VERSION ""

NS_ :

BS_:

BU_: radar Camera ADAS
VAL_TABLE_ vtSig_MCPB_ID 0 "No MCPB" ;
VAL_TABLE_ VtPHASE_VIE 7 "Not used 0x7" 6 "Not used 0x6" 5 "Not used 0x5" 4 "COM_OFF" 3 "Wake / Reveil" 2 "SwitchToStandby / Mise en Veille" 1 "Normal" 0 "Standby / Veille" ;
VAL_TABLE_ LaneCrossing_valueTable 1 "crossing" 0 "not crossing" ;
VAL_TABLE_ LaneModuleValid_vlaueTable 1 "valid" 0 "not valid" ;
VAL_TABLE_ CloseRangeCutIn_ValueTable 1 "Cut in" 0 "No cut in" ;
VAL_TABLE_ LaneMoveType_valueTable 3 "Right movement" 2 "Left movement" 1 "Stable" 0 "Undefined" ;
VAL_TABLE_ MotionStatus_valueTable 8 "Moving (oncoming)" 7 "Unknown (oncoming)" 6 "Stopped (oncoming)" 5 "Moving (movable)" 4 "Unknown (movable)" 3 "Stopped (movable)" 2 "Parked (never moved lights off)" 1 "Standing (never moved lights on)" 0 "Not defined" ;
VAL_TABLE_ PedInDangerZone_valueTable 3 "Invalid" 1 "Pedestrian in danger zone" 0 "No pedestrian in danger zone" ;
VAL_TABLE_ Ped_FCW_on_valueTable 3 "Invalid" 1 "Warning active" 0 "No warning" ;
VAL_TABLE_ FCW_on_valueTable 1 "Warning active" 0 "No warning" ;
VAL_TABLE_ VLviewRangeAvail_valueTable 1 "available" 0 "not available" ;
VAL_TABLE_ VLlaneType_valueTable 6 "road edge" 5 "bott's dotts" 4 "double lane mark" 3 "solid" 2 "dashed" 1 "undecided" 0 "invalid" ;
VAL_TABLE_ VLquality_valueTable 1 "high" 0 "low" ;
VAL_TABLE_ Failsafe_valueTable 16 "partial transparent" 8 "partial blockage" 4 "low sun" 2 "saturated image" 1 "blurred image" ;
VAL_TABLE_ DayTimeIndicator_valueTable 2 "night" 1 "dusk" 0 "day" ;
VAL_TABLE_ VOreplacedObject_valueTable 1 "replaced" 0 "not replaced" ;
VAL_TABLE_ VOcutInAndOut_valueTable 4 "cut out" 3 "cut in" 2 "out host lane" 1 "in host lane" 0 "undefined" ;
VAL_TABLE_ VOvalid_valueTable 1 "new valid" 0 "older valid" ;
VAL_TABLE_ VOmotionStatus_valueTable 5 "parked" 4 "oncoming" 3 "moving" 2 "stopped" 1 "standing" 0 "not defined" ;
VAL_TABLE_ VObrakeLight_valueTable 2 "on" 1 "off" 0 "not available" ;
VAL_TABLE_ VOindicator_valueTable 4 "both" 3 "right" 2 "left" 1 "off" 0 "not available" ;
VAL_TABLE_ VOlane_valueTable 3 "invalid" 2 "next lane" 1 "ego" 0 "not assigned" ;
VAL_TABLE_ VOisValid_valueTable 1 "object" 0 "no object" ;
VAL_TABLE_ VOclass_valueTable 5 "pedestrian" 4 "bicycle" 3 "motorbike" 2 "car" 1 "truck" 0 "undecided" ;
VAL_TABLE_ RoadType_valueTable 2 "inner city" 1 "highway" 0 "unknown" ;
VAL_TABLE_ ConstructionArea_valueTable 1 "construction area" 0 "not construction area" ;
VAL_TABLE_ Maintenance_valueTable 1 "permanent failure" 0 "ok" ;

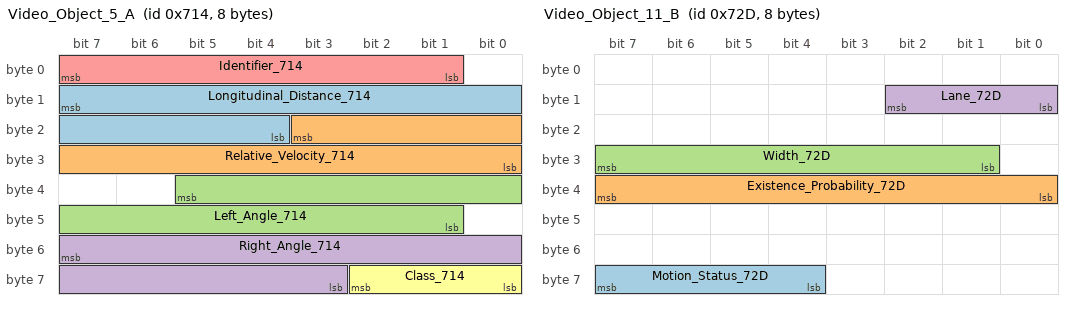
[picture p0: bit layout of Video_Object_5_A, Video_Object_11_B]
BO_ 1812 Video_Object_5_A: 8 Camera
 SG_ Longitudinal_Distance_714 : 15|12@0+ (0.05,0) [0|204.75] "m"  ADAS,radar
 SG_ Relative_Velocity_714 : 19|12@0- (0.05,0) [-102.4|102.35] "m/s"  ADAS,radar
 SG_ Left_Angle_714 : 37|13@0- (0.0002,0) [-0.8192|0.819] "rad"  ADAS,radar
 SG_ Right_Angle_714 : 55|13@0- (0.0002,0) [-0.8192|0.819] "rad"  ADAS,radar
 SG_ Identifier_714 : 7|7@0+ (1,0) [0|127] ""  ADAS,radar
 SG_ Class_714 : 58|3@0+ (1,0) [0|7] ""  ADAS,radar

BO_ 1078 Video_Object_Header: 6 Camera
 SG_ Number_Of_Objects : 7|5@0+ (1,0) [0|31] ""  radar

BO_ 1837 Video_Object_11_B: 8 Camera
 SG_ Motion_Status_72D : 63|4@0+ (1,0) [0|15] "0"  radar,ADAS
 SG_ Existence_Probability_72D : 39|8@0+ (0.0039215686,0) [0|0.999999] ""  radar,ADAS
 SG_ Width_72D : 31|7@0+ (0.05,0) [0|6.35] ""  radar,ADAS
 SG_ Lane_72D : 10|3@0+ (1,0) [0|7] ""  radar,ADAS

BO_ 1977 DL_Status: 8 radar
 SG_ Stat_StatusType : 7|1@0+ (1,0) [0|1] ""  ADAS

BO_ 1978 DL_Targets: 8 radar
 SG_ ta8_relative_velocity m68 : 21|14@0- (0.01,0) [-81.91|81.91] "m/s"  ADAS
 SG_ ta7_angle_LSB m60 : 63|3@0+ (0.05,0) [0|0.35] ""  ADAS
 SG_ ta18_angle_LSB m148 : 63|3@0+ (0.05,0) [0|0.35] ""  ADAS
 SG_ ta14_relative_velocity m116 : 21|14@0- (0.01,0) [-81.91|81.91] "m/s"  ADAS
 SG_ ta10_relative_velocity m84 : 21|14@0- (0.01,0) [-81.91|81.91] "m/s"  ADAS
 SG_ target_multiplexor M : 7|8@0+ (1,0) [0|255] ""  ADAS
 SG_ ta31_fix_relative_velocity m252 : 21|14@0- (0.01,0) [-81.91|81.91] "m/s"  ADAS
 SG_ ta31_fix_range m252 : 39|16@0+ (0.01,0) [0|655.35] "m"  ADAS
 SG_ ta31_fix_power m252 : 55|8@0+ (0.5,0) [0|127.5] "dB"  ADAS
 SG_ ta31_fix_angle_MSB m252 : 15|8@0- (0.4,0) [-51.15|51.15] ""  ADAS
 SG_ ta31_fix_angle_LSB m252 : 63|3@0+ (0.05,0) [0|0.35] ""  ADAS
 SG_ ta0_power m4 : 55|8@0+ (0.5,0) [0|127.5] "dB"  ADAS
 SG_ ta1_power m12 : 55|8@0+ (0.5,0) [0|127.5] "dB"  ADAS
 SG_ ta2_power m20 : 55|8@0+ (0.5,0) [0|127.5] "dB"  ADAS
 SG_ ta3_power m28 : 55|8@0+ (0.5,0) [0|127.5] "dB"  ADAS
 SG_ ta4_power m36 : 55|8@0+ (0.5,0) [0|127.5] "dB"  ADAS
 SG_ ta5_power m44 : 55|8@0+ (0.5,0) [0|127.5] "dB"  ADAS
 SG_ ta6_power m52 : 55|8@0+ (0.5,0) [0|127.5] "dB"  ADAS
 SG_ ta7_power m60 : 55|8@0+ (0.5,0) [0|127.5] "dB"  ADAS
 SG_ ta8_power m68 : 55|8@0+ (0.5,0) [0|127.5] "dB"  ADAS
 SG_ ta9_power m76 : 55|8@0+ (0.5,0) [0|127.5] "dB"  ADAS
 SG_ ta10_power m84 : 55|8@0+ (0.5,0) [0|127.5] "dB"  ADAS
 SG_ ta11_power m92 : 55|8@0+ (0.5,0) [0|127.5] "dB"  ADAS
 SG_ ta12_power m100 : 55|8@0+ (0.5,0) [0|127.5] "dB"  ADAS
 SG_ ta13_power m108 : 55|8@0+ (0.5,0) [0|127.5] "dB"  ADAS
 SG_ ta14_power m116 : 55|8@0+ (0.5,0) [0|127.5] "dB"  ADAS
 SG_ ta15_power m124 : 55|8@0+ (0.5,0) [0|127.5] "dB"  ADAS
 SG_ ta16_power m132 : 55|8@0+ (0.5,0) [0|127.5] "dB"  ADAS
 SG_ ta17_power m140 : 55|8@0+ (0.5,0) [0|127.5] "dB"  ADAS
 SG_ ta18_power m148 : 55|8@0+ (0.5,0) [0|127.5] "dB"  ADAS
 SG_ ta19_power m156 : 55|8@0+ (0.5,0) [0|127.5] "dB"  ADAS
 SG_ ta20_power m164 : 55|8@0+ (0.5,0) [0|127.5] "dB"  ADAS
 SG_ ta21_power m172 : 55|8@0+ (0.5,0) [0|127.5] "dB"  ADAS
 SG_ ta22_power m180 : 55|8@0+ (0.5,0) [0|127.5] "dB"  ADAS
 SG_ ta23_power m188 : 55|8@0+ (0.5,0) [0|127.5] "dB"  ADAS
 SG_ ta24_power m196 : 55|8@0+ (0.5,0) [0|127.5] "dB"  ADAS
 SG_ ta25_power m204 : 55|8@0+ (0.5,0) [0|127.5] "dB"  ADAS
 SG_ ta26_power m212 : 55|8@0+ (0.5,0) [0|127.5] "dB"  ADAS
 SG_ ta27_power m220 : 55|8@0+ (0.5,0) [0|127.5] "dB"  ADAS
 SG_ ta28_power m228 : 55|8@0+ (0.5,0) [0|127.5] "dB"  ADAS
 SG_ ta29_power m236 : 55|8@0+ (0.5,0) [0|127.5] "dB"  ADAS
 SG_ ta30_power m244 : 55|8@0+ (0.5,0) [0|127.5] "dB"  ADAS
 SG_ ta0_range m4 : 39|16@0+ (0.01,0) [0|655.35] "m"  ADAS
 SG_ ta1_range m12 : 39|16@0+ (0.01,0) [0|655.35] "m"  ADAS
 SG_ ta2_range m20 : 39|16@0+ (0.01,0) [0|655.35] "m"  ADAS
 SG_ ta3_range m28 : 39|16@0+ (0.01,0) [0|655.35] "m"  ADAS
 SG_ ta4_range m36 : 39|16@0+ (0.01,0) [0|655.35] "m"  ADAS
 SG_ ta5_range m44 : 39|16@0+ (0.01,0) [0|655.35] "m"  ADAS
 SG_ ta6_range m52 : 39|16@0+ (0.01,0) [0|655.35] "m"  ADAS
 SG_ ta7_range m60 : 39|16@0+ (0.01,0) [0|655.35] "m"  ADAS
 SG_ ta8_range m68 : 39|16@0+ (0.01,0) [0|655.35] "m"  ADAS
 SG_ ta9_range m76 : 39|16@0+ (0.01,0) [0|655.35] "m"  ADAS
 SG_ ta10_range m84 : 39|16@0+ (0.01,0) [0|655.35] "m"  ADAS
 SG_ ta11_range m92 : 39|16@0+ (0.01,0) [0|655.35] "m"  ADAS
 SG_ ta12_range m100 : 39|16@0+ (0.01,0) [0|655.35] "m"  ADAS
 SG_ ta13_range m108 : 39|16@0+ (0.01,0) [0|655.35] "m"  ADAS
 SG_ ta14_range m116 : 39|16@0+ (0.01,0) [0|655.35] "m"  ADAS
 SG_ ta15_range m124 : 39|16@0+ (0.01,0) [0|655.35] "m"  ADAS
 SG_ ta16_range m132 : 39|16@0+ (0.01,0) [0|655.35] "m"  ADAS
 SG_ ta17_range m140 : 39|16@0+ (0.01,0) [0|655.35] "m"  ADAS
 SG_ ta18_range m148 : 39|16@0+ (0.01,0) [0|655.35] "m"  ADAS
 SG_ ta19_range m156 : 39|16@0+ (0.01,0) [0|655.35] "m"  ADAS
 SG_ ta20_range m164 : 39|16@0+ (0.01,0) [0|655.35] "m"  ADAS
 SG_ ta21_range m172 : 39|16@0+ (0.01,0) [0|655.35] "m"  ADAS
 SG_ ta22_range m180 : 39|16@0+ (0.01,0) [0|655.35] "m"  ADAS
 SG_ ta23_range m188 : 39|16@0+ (0.01,0) [0|655.35] "m"  ADAS
 SG_ ta24_range m196 : 39|16@0+ (0.01,0) [0|655.35] "m"  ADAS
 SG_ ta25_range m204 : 39|16@0+ (0.01,0) [0|655.35] "m"  ADAS
 SG_ ta26_range m212 : 39|16@0+ (0.01,0) [0|655.35] "m"  ADAS
 SG_ ta27_range m220 : 39|16@0+ (0.01,0) [0|655.35] "m"  ADAS
 SG_ ta28_range m228 : 39|16@0+ (0.01,0) [0|655.35] "m"  ADAS
 SG_ ta29_range m236 : 39|16@0+ (0.01,0) [0|655.35] "m"  ADAS
 SG_ ta30_range m244 : 39|16@0+ (0.01,0) [0|655.35] "m"  ADAS
 SG_ ta0_relative_velocity m4 : 21|14@0- (0.01,0) [-81.91|81.91] "m/s"  ADAS
 SG_ ta1_relative_velocity m12 : 21|14@0- (0.01,0) [-81.91|81.91] "m/s"  ADAS
 SG_ ta2_relative_velocity m20 : 21|14@0- (0.01,0) [-81.91|81.91] "m/s"  ADAS
 SG_ ta3_relative_velocity m28 : 21|14@0- (0.01,0) [-81.91|81.91] "m/s"  ADAS
 SG_ ta4_relative_velocity m36 : 21|14@0- (0.01,0) [-81.91|81.91] "m/s"  ADAS
 SG_ ta5_relative_velocity m44 : 21|14@0- (0.01,0) [-81.91|81.91] "m/s"  ADAS
 SG_ ta6_relative_velocity m52 : 21|14@0- (0.01,0) [-81.91|81.91] "m/s"  ADAS
 SG_ ta7_relative_velocity m60 : 21|14@0- (0.01,0) [-81.91|81.91] "m/s"  ADAS
 SG_ ta9_relative_velocity m76 : 21|14@0- (0.01,0) [-81.91|81.91] "m/s"  ADAS
 SG_ ta11_relative_velocity m92 : 21|14@0- (0.01,0) [-81.91|81.91] "m/s"  ADAS
 SG_ ta12_relative_velocity m100 : 21|14@0- (0.01,0) [-81.91|81.91] "m/s"  ADAS
 SG_ ta13_relative_velocity m108 : 21|14@0- (0.01,0) [-81.91|81.91] "m/s"  ADAS
 SG_ ta15_relative_velocity m124 : 21|14@0- (0.01,0) [-81.91|81.91] "m/s"  ADAS
 SG_ ta16_relative_velocity m132 : 21|14@0- (0.01,0) [-81.91|81.91] "m/s"  ADAS
 SG_ ta17_relative_velocity m140 : 21|14@0- (0.01,0) [-81.91|81.91] "m/s"  ADAS
 SG_ ta18_relative_velocity m148 : 21|14@0- (0.01,0) [-81.91|81.91] "m/s"  ADAS
 SG_ ta19_relative_velocity m156 : 21|14@0- (0.01,0) [-81.91|81.91] "m/s"  ADAS
 SG_ ta20_relative_velocity m164 : 21|14@0- (0.01,0) [-81.91|81.91] "m/s"  ADAS
 SG_ ta21_relative_velocity m172 : 21|14@0- (0.01,0) [-81.91|81.91] "m/s"  ADAS
 SG_ ta22_relative_velocity m180 : 21|14@0- (0.01,0) [-81.91|81.91] "m/s"  ADAS
 SG_ ta23_relative_velocity m188 : 21|14@0- (0.01,0) [-81.91|81.91] "m/s"  ADAS
 SG_ ta24_relative_velocity m196 : 21|14@0- (0.01,0) [-81.91|81.91] "m/s"  ADAS
 SG_ ta25_relative_velocity m204 : 21|14@0- (0.01,0) [-81.91|81.91] "m/s"  ADAS
 SG_ ta26_relative_velocity m212 : 21|14@0- (0.01,0) [-81.91|81.91] "m/s"  ADAS
 SG_ ta27_relative_velocity m220 : 21|14@0- (0.01,0) [-81.91|81.91] "m/s"  ADAS
 SG_ ta28_relative_velocity m228 : 21|14@0- (0.01,0) [-81.91|81.91] "m/s"  ADAS
 SG_ ta29_relative_velocity m236 : 21|14@0- (0.01,0) [-81.91|81.91] "m/s"  ADAS
 SG_ ta30_relative_velocity m244 : 21|14@0- (0.01,0) [-81.91|81.91] "m/s"  ADAS
 SG_ ta0_angle_LSB m4 : 63|3@0+ (0.05,0) [0|0.35] ""  ADAS
 SG_ ta1_angle_LSB m12 : 63|3@0+ (0.05,0) [0|0.35] ""  ADAS
 SG_ ta2_angle_LSB m20 : 63|3@0+ (0.05,0) [0|0.35] ""  ADAS
 SG_ ta3_angle_LSB m28 : 63|3@0+ (0.05,0) [0|0.35] ""  ADAS
 SG_ ta4_angle_LSB m36 : 63|3@0+ (0.05,0) [0|0.35] ""  ADAS
 SG_ ta5_angle_LSB m44 : 63|3@0+ (0.05,0) [0|0.35] ""  ADAS
 SG_ ta6_angle_LSB m52 : 63|3@0+ (0.05,0) [0|0.35] ""  ADAS
 SG_ ta8_angle_LSB m68 : 63|3@0+ (0.05,0) [0|0.35] ""  ADAS
 SG_ ta9_angle_LSB m76 : 63|3@0+ (0.05,0) [0|0.35] ""  ADAS
 SG_ ta10_angle_LSB m84 : 63|3@0+ (0.05,0) [0|0.35] ""  ADAS
 SG_ ta11_angle_LSB m92 : 63|3@0+ (0.05,0) [0|0.35] ""  ADAS
 SG_ ta12_angle_LSB m100 : 63|3@0+ (0.05,0) [0|0.35] ""  ADAS
 SG_ ta13_angle_LSB m108 : 63|3@0+ (0.05,0) [0|0.35] ""  ADAS
 SG_ ta14_angle_LSB m116 : 63|3@0+ (0.05,0) [0|0.35] ""  ADAS
 SG_ ta15_angle_LSB m124 : 63|3@0+ (0.05,0) [0|0.35] ""  ADAS
 SG_ ta16_angle_LSB m132 : 63|3@0+ (0.05,0) [0|0.35] ""  ADAS
 SG_ ta17_angle_LSB m140 : 63|3@0+ (0.05,0) [0|0.35] ""  ADAS
 SG_ ta19_angle_LSB m156 : 63|3@0+ (0.05,0) [0|0.35] ""  ADAS
 SG_ ta20_angle_LSB m164 : 63|3@0+ (0.05,0) [0|0.35] ""  ADAS
 SG_ ta21_angle_LSB m172 : 63|3@0+ (0.05,0) [0|0.35] ""  ADAS
 SG_ ta22_angle_LSB m180 : 63|3@0+ (0.05,0) [0|0.35] ""  ADAS
 SG_ ta23_angle_LSB m188 : 63|3@0+ (0.05,0) [0|0.35] ""  ADAS
 SG_ ta24_angle_LSB m196 : 63|3@0+ (0.05,0) [0|0.35] ""  ADAS
 SG_ ta25_angle_LSB m204 : 63|3@0+ (0.05,0) [0|0.35] ""  ADAS
 SG_ ta26_angle_LSB m212 : 63|3@0+ (0.05,0) [0|0.35] ""  ADAS
 SG_ ta27_angle_LSB m220 : 63|3@0+ (0.05,0) [0|0.35] ""  ADAS
 SG_ ta28_angle_LSB m228 : 63|3@0+ (0.05,0) [0|0.35] ""  ADAS
 SG_ ta29_angle_LSB m236 : 63|3@0+ (0.05,0) [0|0.35] ""  ADAS
 SG_ ta30_angle_LSB m244 : 63|3@0+ (0.05,0) [0|0.35] ""  ADAS
 SG_ ta0_angle_MSB m4 : 15|8@0- (0.4,0) [-51.15|51.15] ""  ADAS
 SG_ ta1_angle_MSB m12 : 15|8@0- (0.4,0) [-51.15|51.15] ""  ADAS
 SG_ ta2_angle_MSB m20 : 15|8@0- (0.4,0) [-51.15|51.15] ""  ADAS
 SG_ ta3_angle_MSB m28 : 15|8@0- (0.4,0) [-51.15|51.15] ""  ADAS
 SG_ ta4_angle_MSB m36 : 15|8@0- (0.4,0) [-51.15|51.15] ""  ADAS
 SG_ ta5_angle_MSB m44 : 15|8@0- (0.4,0) [-51.15|51.15] ""  ADAS
 SG_ ta6_angle_MSB m52 : 15|8@0- (0.4,0) [-51.15|51.15] ""  ADAS
 SG_ ta7_angle_MSB m60 : 15|8@0- (0.4,0) [-51.15|51.15] ""  ADAS
 SG_ ta8_angle_MSB m68 : 15|8@0- (0.4,0) [-51.15|51.15] ""  ADAS
 SG_ ta9_angle_MSB m76 : 15|8@0- (0.4,0) [-51.15|51.15] ""  ADAS
 SG_ ta10_angle_MSB m84 : 15|8@0- (0.4,0) [-51.15|51.15] ""  ADAS
 SG_ ta11_angle_MSB m92 : 15|8@0- (0.4,0) [-51.15|51.15] ""  ADAS
 SG_ ta12_angle_MSB m100 : 15|8@0- (0.4,0) [-51.15|51.15] ""  ADAS
 SG_ ta13_angle_MSB m108 : 15|8@0- (0.4,0) [-51.15|51.15] ""  ADAS
 SG_ ta14_angle_MSB m116 : 15|8@0- (0.4,0) [-51.15|51.15] ""  ADAS
 SG_ ta15_angle_MSB m124 : 15|8@0- (0.4,0) [-51.15|51.15] ""  ADAS
 SG_ ta16_angle_MSB m132 : 15|8@0- (0.4,0) [-51.15|51.15] ""  ADAS
 SG_ ta17_angle_MSB m140 : 15|8@0- (0.4,0) [-51.15|51.15] ""  ADAS
 SG_ ta18_angle_MSB m148 : 15|8@0- (0.4,0) [-51.15|51.15] ""  ADAS
 SG_ ta19_angle_MSB m156 : 15|8@0- (0.4,0) [-51.15|51.15] ""  ADAS
 SG_ ta20_angle_MSB m164 : 15|8@0- (0.4,0) [-51.15|51.15] ""  ADAS
 SG_ ta21_angle_MSB m172 : 15|8@0- (0.4,0) [-51.15|51.15] ""  ADAS
 SG_ ta22_angle_MSB m180 : 15|8@0- (0.4,0) [-51.15|51.15] ""  ADAS
 SG_ ta23_angle_MSB m188 : 15|8@0- (0.4,0) [-51.15|51.15] ""  ADAS
 SG_ ta24_angle_MSB m196 : 15|8@0- (0.4,0) [-51.15|51.15] ""  ADAS
 SG_ ta25_angle_MSB m204 : 15|8@0- (0.4,0) [-51.15|51.15] ""  ADAS
 SG_ ta26_angle_MSB m212 : 15|8@0- (0.4,0) [-51.15|51.15] ""  ADAS
 SG_ ta27_angle_MSB m220 : 15|8@0- (0.4,0) [-51.15|51.15] ""  ADAS
 SG_ ta28_angle_MSB m228 : 15|8@0- (0.4,0) [-51.15|51.15] ""  ADAS
 SG_ ta29_angle_MSB m236 : 15|8@0- (0.4,0) [-51.15|51.15] ""  ADAS
 SG_ ta30_angle_MSB m244 : 15|8@0- (0.4,0) [-51.15|51.15] ""  ADAS

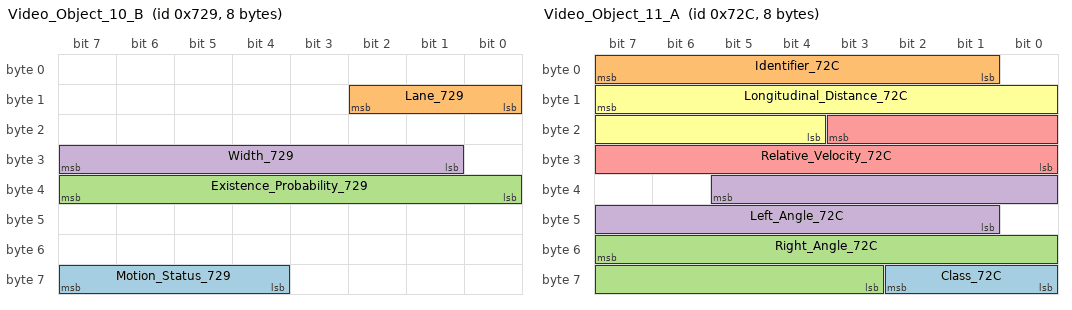
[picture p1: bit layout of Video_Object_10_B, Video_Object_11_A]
BO_ 1833 Video_Object_10_B: 8 Camera
 SG_ Motion_Status_729 : 63|4@0+ (1,0) [0|15] ""  radar,ADAS
 SG_ Lane_729 : 10|3@0+ (1,0) [0|7] ""  radar,ADAS
 SG_ Existence_Probability_729 : 39|8@0+ (0.0039215686,0) [0|0.999999993] ""  radar,ADAS
 SG_ Width_729 : 31|7@0+ (0.05,0) [0|6.35] "m"  radar,ADAS

BO_ 1836 Video_Object_11_A: 8 Camera
 SG_ Class_72C : 58|3@0+ (1,0) [0|7] ""  radar,ADAS
 SG_ Identifier_72C : 7|7@0+ (1,0) [0|127] ""  radar,ADAS
 SG_ Right_Angle_72C : 55|13@0- (0.0002,0) [-0.8192|0.819] "rad"  radar,ADAS
 SG_ Left_Angle_72C : 37|13@0- (0.0002,0) [-0.8192|0.819] "rad"  radar,ADAS
 SG_ Relative_Velocity_72C : 19|12@0- (0.05,0) [-102.4|102.35] "m/s"  radar,ADAS
 SG_ Longitudinal_Distance_72C : 15|12@0+ (0.05,0) [0|204.75] "m"  radar,ADAS

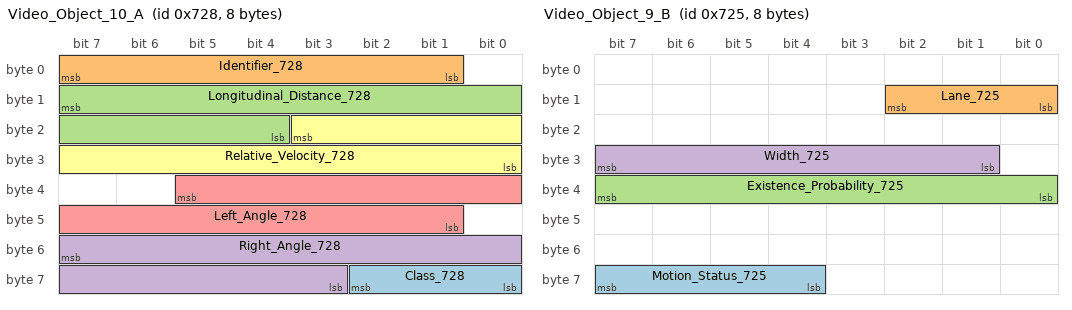
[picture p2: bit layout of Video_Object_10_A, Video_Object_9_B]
BO_ 1832 Video_Object_10_A: 8 Camera
 SG_ Class_728 : 58|3@0+ (1,0) [0|7] ""  radar,ADAS
 SG_ Identifier_728 : 7|7@0+ (1,0) [0|127] ""  radar,ADAS
 SG_ Longitudinal_Distance_728 : 15|12@0+ (0.05,0) [0|204.75] "m"  radar,ADAS
 SG_ Right_Angle_728 : 55|13@0- (0.0002,0) [-0.8192|0.819] "rad"  radar,ADAS
 SG_ Left_Angle_728 : 37|13@0- (0.0002,0) [-0.8192|0.819] "rad"  radar,ADAS
 SG_ Relative_Velocity_728 : 19|12@0- (0.05,0) [-102.4|102.35] "m/s"  radar,ADAS

BO_ 1829 Video_Object_9_B: 8 Camera
 SG_ Motion_Status_725 : 63|4@0+ (1,0) [0|15] ""  radar,ADAS
 SG_ Lane_725 : 10|3@0+ (1,0) [0|7] ""  radar,ADAS
 SG_ Existence_Probability_725 : 39|8@0+ (0.0039215686,0) [0|0.999999993] ""  radar,ADAS
 SG_ Width_725 : 31|7@0+ (0.05,0) [0|6.35] "m"  radar,ADAS

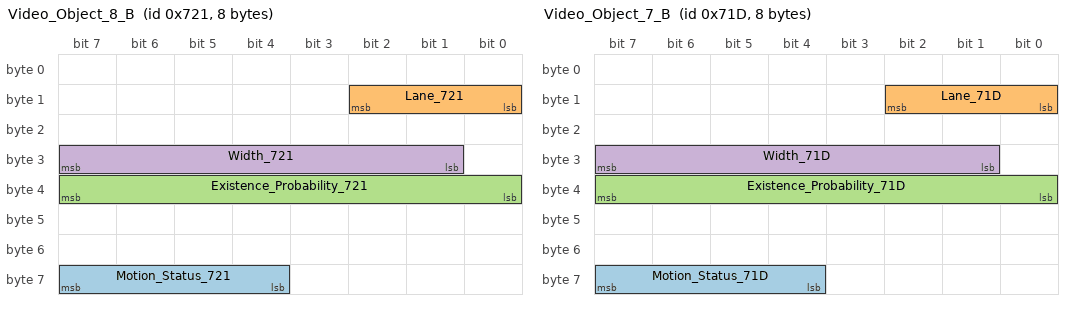
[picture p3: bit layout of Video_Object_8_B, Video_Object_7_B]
BO_ 1825 Video_Object_8_B: 8 Camera
 SG_ Motion_Status_721 : 63|4@0+ (1,0) [0|15] ""  radar,ADAS
 SG_ Lane_721 : 10|3@0+ (1,0) [0|7] ""  radar,ADAS
 SG_ Existence_Probability_721 : 39|8@0+ (0.0039215686,0) [0|0.999999993] ""  radar,ADAS
 SG_ Width_721 : 31|7@0+ (0.05,0) [0|6.35] "m"  radar,ADAS

BO_ 1821 Video_Object_7_B: 8 Camera
 SG_ Motion_Status_71D : 63|4@0+ (1,0) [0|15] ""  radar,ADAS
 SG_ Lane_71D : 10|3@0+ (1,0) [0|7] ""  radar,ADAS
 SG_ Existence_Probability_71D : 39|8@0+ (0.0039215686,0) [0|0.999999993] ""  radar,ADAS
 SG_ Width_71D : 31|7@0+ (0.05,0) [0|6.35] "m"  radar,ADAS

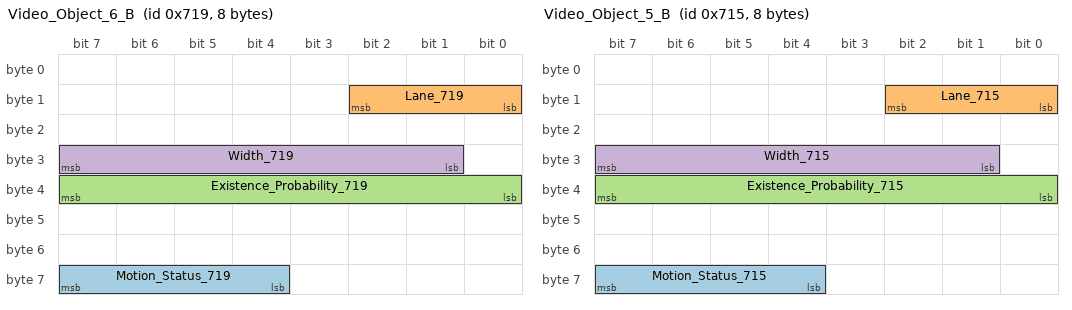
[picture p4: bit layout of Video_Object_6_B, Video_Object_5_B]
BO_ 1817 Video_Object_6_B: 8 Camera
 SG_ Motion_Status_719 : 63|4@0+ (1,0) [0|15] ""  radar,ADAS
 SG_ Lane_719 : 10|3@0+ (1,0) [0|7] ""  radar,ADAS
 SG_ Existence_Probability_719 : 39|8@0+ (0.0039215686,0) [0|0.999999993] ""  radar,ADAS
 SG_ Width_719 : 31|7@0+ (0.05,0) [0|6.35] "m"  radar,ADAS

BO_ 1813 Video_Object_5_B: 8 Camera
 SG_ Motion_Status_715 : 63|4@0+ (1,0) [0|15] ""  radar,ADAS
 SG_ Lane_715 : 10|3@0+ (1,0) [0|7] ""  radar,ADAS
 SG_ Existence_Probability_715 : 39|8@0+ (0.0039215686,0) [0|0.999999993] ""  radar,ADAS
 SG_ Width_715 : 31|7@0+ (0.05,0) [0|6.35] "m"  radar,ADAS

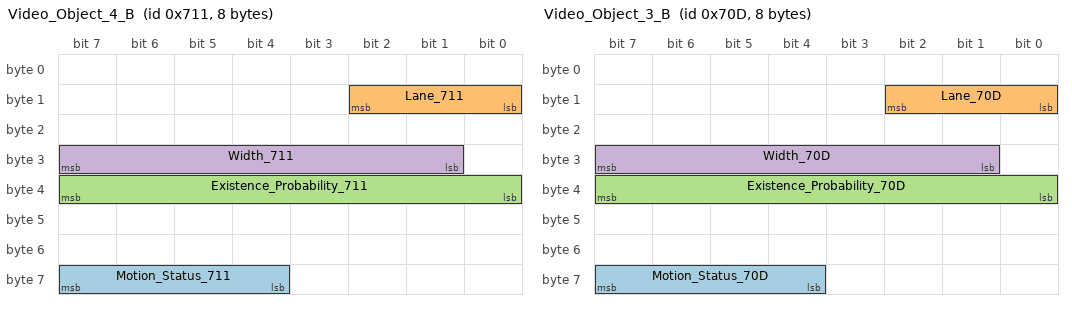
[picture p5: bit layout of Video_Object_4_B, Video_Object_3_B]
BO_ 1809 Video_Object_4_B: 8 Camera
 SG_ Motion_Status_711 : 63|4@0+ (1,0) [0|15] ""  radar,ADAS
 SG_ Lane_711 : 10|3@0+ (1,0) [0|7] ""  radar,ADAS
 SG_ Existence_Probability_711 : 39|8@0+ (0.0039215686,0) [0|0.999999993] ""  radar,ADAS
 SG_ Width_711 : 31|7@0+ (0.05,0) [0|6.35] "m"  radar,ADAS

BO_ 1805 Video_Object_3_B: 8 Camera
 SG_ Motion_Status_70D : 63|4@0+ (1,0) [0|15] ""  radar,ADAS
 SG_ Lane_70D : 10|3@0+ (1,0) [0|7] ""  radar,ADAS
 SG_ Existence_Probability_70D : 39|8@0+ (0.0039215686,0) [0|0.999999993] ""  radar,ADAS
 SG_ Width_70D : 31|7@0+ (0.05,0) [0|6.35] "m"  radar,ADAS

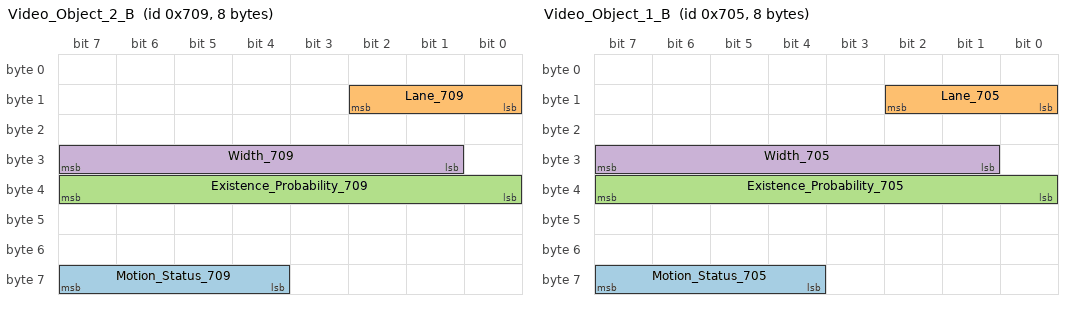
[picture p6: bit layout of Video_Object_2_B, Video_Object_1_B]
BO_ 1801 Video_Object_2_B: 8 Camera
 SG_ Motion_Status_709 : 63|4@0+ (1,0) [0|15] ""  radar,ADAS
 SG_ Lane_709 : 10|3@0+ (1,0) [0|7] ""  radar,ADAS
 SG_ Existence_Probability_709 : 39|8@0+ (0.0039215686,0) [0|0.999999993] ""  radar,ADAS
 SG_ Width_709 : 31|7@0+ (0.05,0) [0|6.35] "m"  radar,ADAS

BO_ 1797 Video_Object_1_B: 8 Camera
 SG_ Motion_Status_705 : 63|4@0+ (1,0) [0|15] ""  radar,ADAS
 SG_ Lane_705 : 10|3@0+ (1,0) [0|7] ""  radar,ADAS
 SG_ Existence_Probability_705 : 39|8@0+ (0.0039215686,0) [0|0.999999993] ""  radar,ADAS
 SG_ Width_705 : 31|7@0+ (0.05,0) [0|6.35] "m"  radar,ADAS

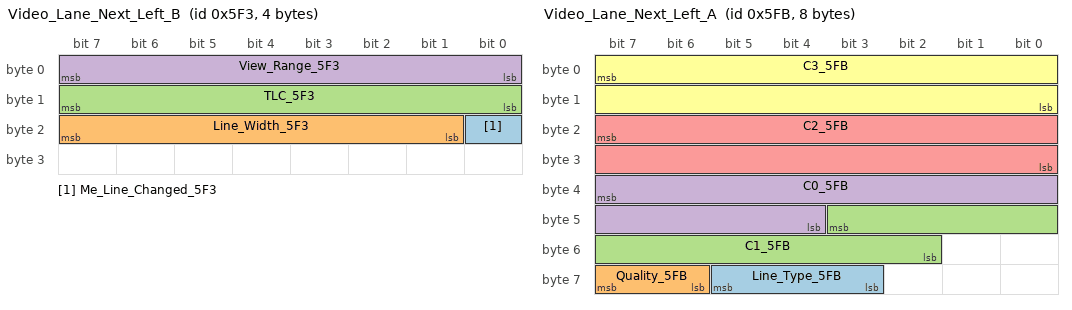
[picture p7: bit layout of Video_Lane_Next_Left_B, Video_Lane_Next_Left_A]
BO_ 1523 Video_Lane_Next_Left_B: 4 Camera
 SG_ Me_Line_Changed_5F3 : 16|1@0+ (1,0) [0|1] ""  radar,ADAS
 SG_ Line_Width_5F3 : 23|7@0+ (0.01,0) [0|1.27] "m"  radar,ADAS
 SG_ TLC_5F3 : 15|8@0+ (0.01,0) [0|2.55] "s"  radar,ADAS
 SG_ View_Range_5F3 : 7|8@0+ (0.5,0) [0|127.5] "m"  radar,ADAS

BO_ 1531 Video_Lane_Next_Left_A: 8 Camera
 SG_ Line_Type_5FB : 61|3@0+ (1,0) [0|7] ""  radar,ADAS
 SG_ Quality_5FB : 63|2@0+ (1,0) [0|3] ""  radar,ADAS
 SG_ C1_5FB : 43|10@0- (0.0009765625,0) [-0.357|0.357] ""  radar,ADAS
 SG_ C0_5FB : 39|12@0- (0.01,0) [-20.48|20.47] "m"  radar,ADAS
 SG_ C2_5FB : 23|16@0- (1E-006,0) [-0.032768|0.032766] "m-1"  radar,ADAS
 SG_ C3_5FB : 7|16@0- (4E-009,0) [-0.000131072|0.000131068] "m-2"  radar,ADAS

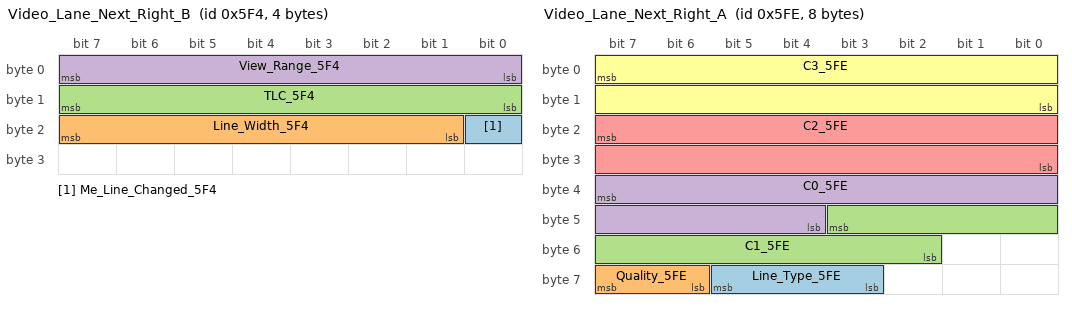
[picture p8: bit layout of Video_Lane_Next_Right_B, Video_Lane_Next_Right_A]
BO_ 1524 Video_Lane_Next_Right_B: 4 Camera
 SG_ Me_Line_Changed_5F4 : 16|1@0+ (1,0) [0|1] ""  radar,ADAS
 SG_ Line_Width_5F4 : 23|7@0+ (0.01,0) [0|1.27] "m"  radar,ADAS
 SG_ TLC_5F4 : 15|8@0+ (0.01,0) [0|2.55] "s"  radar,ADAS
 SG_ View_Range_5F4 : 7|8@0+ (0.5,0) [0|127.5] "m"  radar,ADAS

BO_ 1534 Video_Lane_Next_Right_A: 8 Camera
 SG_ Line_Type_5FE : 61|3@0+ (1,0) [0|7] ""  radar,ADAS
 SG_ Quality_5FE : 63|2@0+ (1,0) [0|3] ""  radar,ADAS
 SG_ C1_5FE : 43|10@0- (0.0009765625,0) [-0.357|0.357] ""  radar,ADAS
 SG_ C0_5FE : 39|12@0- (0.01,0) [-20.48|20.47] "m"  radar,ADAS
 SG_ C2_5FE : 23|16@0- (1E-006,0) [-0.032768|0.032766] "m-1"  radar,ADAS
 SG_ C3_5FE : 7|16@0- (4E-009,0) [-0.000131072|0.000131068] "m-2"  radar,ADAS

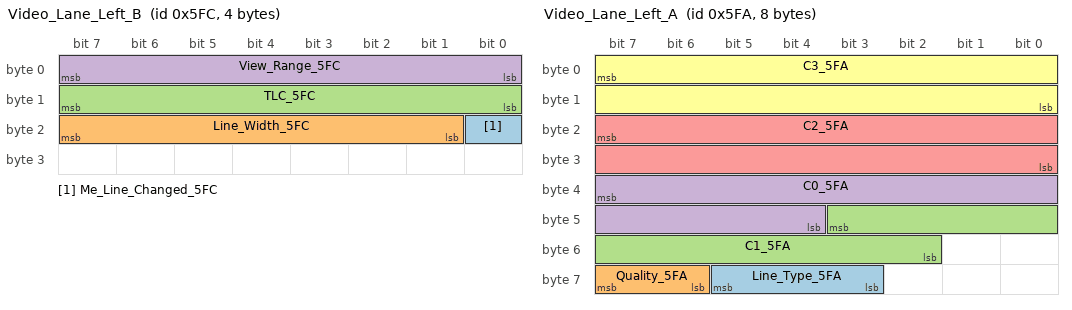
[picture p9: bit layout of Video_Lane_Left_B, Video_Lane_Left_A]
BO_ 1532 Video_Lane_Left_B: 4 Camera
 SG_ Me_Line_Changed_5FC : 16|1@0+ (1,0) [0|1] ""  radar,ADAS
 SG_ Line_Width_5FC : 23|7@0+ (0.01,0) [0|1.27] "m"  radar,ADAS
 SG_ TLC_5FC : 15|8@0+ (0.01,0) [0|2.55] "s"  radar,ADAS
 SG_ View_Range_5FC : 7|8@0+ (0.5,0) [0|127.5] "m"  radar,ADAS

BO_ 1530 Video_Lane_Left_A: 8 Camera
 SG_ Line_Type_5FA : 61|3@0+ (1,0) [0|7] ""  radar,ADAS
 SG_ Quality_5FA : 63|2@0+ (1,0) [0|3] ""  radar,ADAS
 SG_ C1_5FA : 43|10@0- (0.0009765625,0) [-0.357|0.357] ""  radar,ADAS
 SG_ C0_5FA : 39|12@0- (0.01,0) [-20.48|20.47] "m"  radar,ADAS
 SG_ C2_5FA : 23|16@0- (1E-006,0) [-0.032768|0.032766] "m-1"  radar,ADAS
 SG_ C3_5FA : 7|16@0- (4E-009,0) [-0.000131072|0.000131068] "m-2"  radar,ADAS

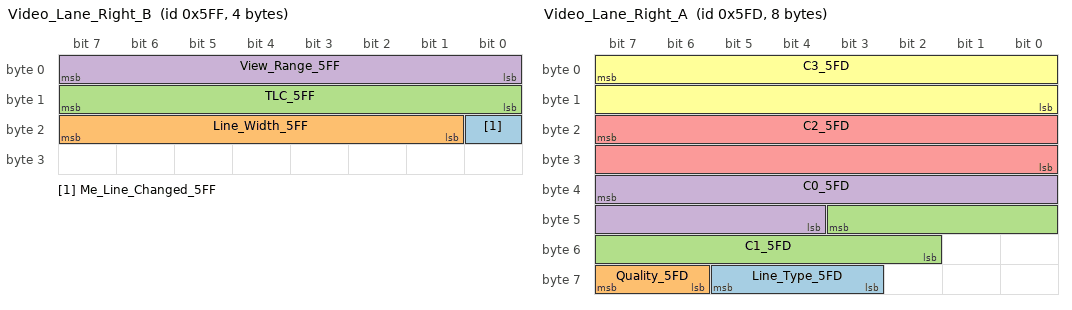
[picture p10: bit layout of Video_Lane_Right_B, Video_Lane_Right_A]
BO_ 1535 Video_Lane_Right_B: 4 Camera
 SG_ Me_Line_Changed_5FF : 16|1@0+ (1,0) [0|1] ""  radar,ADAS
 SG_ Line_Width_5FF : 23|7@0+ (0.01,0) [0|1.27] "m"  radar,ADAS
 SG_ TLC_5FF : 15|8@0+ (0.01,0) [0|2.55] "s"  radar,ADAS
 SG_ View_Range_5FF : 7|8@0+ (0.5,0) [0|127.5] "m"  radar,ADAS

BO_ 1533 Video_Lane_Right_A: 8 Camera
 SG_ Line_Type_5FD : 61|3@0+ (1,0) [0|7] ""  radar,ADAS
 SG_ Quality_5FD : 63|2@0+ (1,0) [0|3] ""  radar,ADAS
 SG_ C1_5FD : 43|10@0- (0.0009765625,0) [-0.357|0.357] ""  radar,ADAS
 SG_ C0_5FD : 39|12@0- (0.01,0) [-20.48|20.47] "m"  radar,ADAS
 SG_ C2_5FD : 23|16@0- (1E-006,0) [-0.032768|0.032766] "m-1"  radar,ADAS
 SG_ C3_5FD : 7|16@0- (4E-009,0) [-0.000131072|0.000131068] "m-2"  radar,ADAS

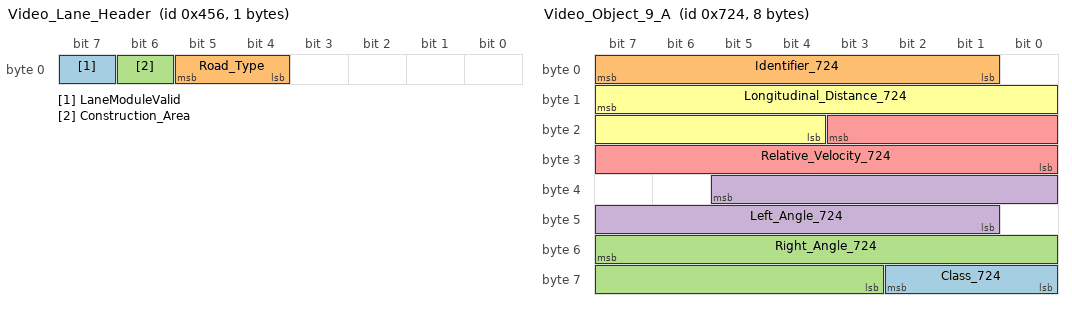
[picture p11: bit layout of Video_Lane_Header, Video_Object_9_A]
BO_ 1110 Video_Lane_Header: 1 Camera
 SG_ LaneModuleValid : 7|1@0+ (1,0) [0|1] ""  radar,ADAS
 SG_ Road_Type : 5|2@0+ (1,0) [0|3] ""  radar,ADAS
 SG_ Construction_Area : 6|1@0+ (1,0) [0|1] ""  radar,ADAS

BO_ 1828 Video_Object_9_A: 8 Camera
 SG_ Class_724 : 58|3@0+ (1,0) [0|7] ""  radar,ADAS
 SG_ Identifier_724 : 7|7@0+ (1,0) [0|127] ""  radar,ADAS
 SG_ Right_Angle_724 : 55|13@0- (0.0002,0) [-0.8192|0.819] "rad"  radar,ADAS
 SG_ Left_Angle_724 : 37|13@0- (0.0002,0) [-0.8192|0.819] "rad"  radar,ADAS
 SG_ Relative_Velocity_724 : 19|12@0- (0.05,0) [-102.4|102.35] "m/s"  radar,ADAS
 SG_ Longitudinal_Distance_724 : 15|12@0+ (0.05,0) [0|204.75] "m"  radar,ADAS

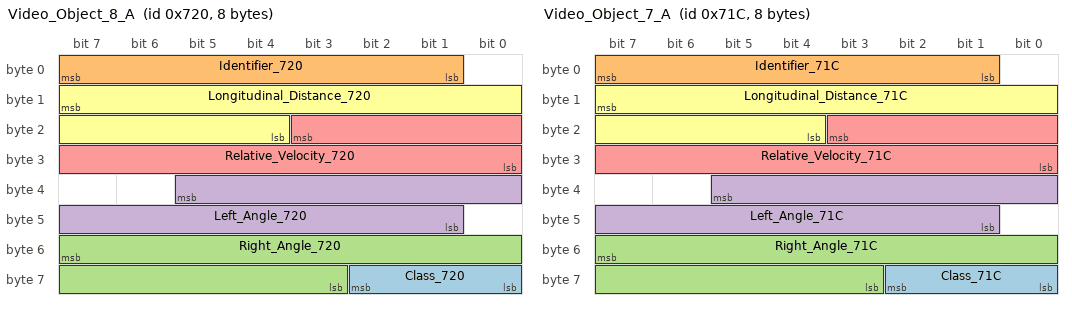
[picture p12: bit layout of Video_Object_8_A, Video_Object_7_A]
BO_ 1824 Video_Object_8_A: 8 Camera
 SG_ Class_720 : 58|3@0+ (1,0) [0|7] ""  radar,ADAS
 SG_ Identifier_720 : 7|7@0+ (1,0) [0|127] ""  radar,ADAS
 SG_ Right_Angle_720 : 55|13@0- (0.0002,0) [-0.8192|0.819] "rad"  radar,ADAS
 SG_ Left_Angle_720 : 37|13@0- (0.0002,0) [-0.8192|0.819] "rad"  radar,ADAS
 SG_ Relative_Velocity_720 : 19|12@0- (0.05,0) [-102.4|102.35] "m/s"  radar,ADAS
 SG_ Longitudinal_Distance_720 : 15|12@0+ (0.05,0) [0|204.75] "m"  radar,ADAS

BO_ 1820 Video_Object_7_A: 8 Camera
 SG_ Class_71C : 58|3@0+ (1,0) [0|7] ""  radar,ADAS
 SG_ Identifier_71C : 7|7@0+ (1,0) [0|127] ""  radar,ADAS
 SG_ Right_Angle_71C : 55|13@0- (0.0002,0) [-0.8192|0.819] "rad"  radar,ADAS
 SG_ Left_Angle_71C : 37|13@0- (0.0002,0) [-0.8192|0.819] "rad"  radar,ADAS
 SG_ Relative_Velocity_71C : 19|12@0- (0.05,0) [-102.4|102.35] "m/s"  radar,ADAS
 SG_ Longitudinal_Distance_71C : 15|12@0+ (0.05,0) [0|204.75] "m"  radar,ADAS

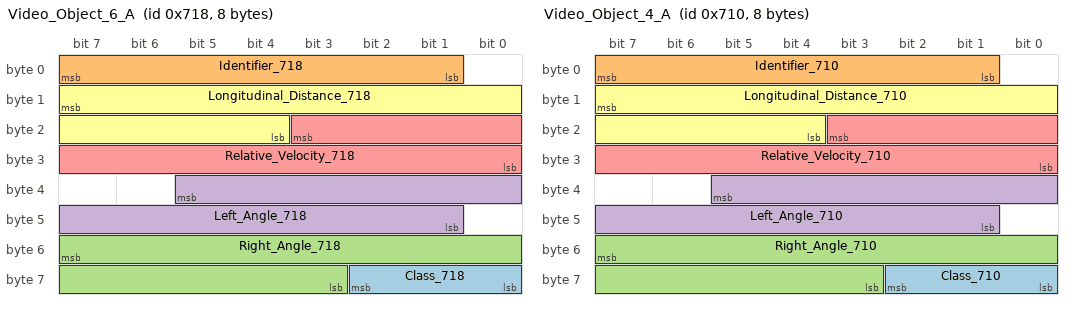
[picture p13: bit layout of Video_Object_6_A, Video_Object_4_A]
BO_ 1816 Video_Object_6_A: 8 Camera
 SG_ Class_718 : 58|3@0+ (1,0) [0|7] ""  radar,ADAS
 SG_ Identifier_718 : 7|7@0+ (1,0) [0|127] ""  radar,ADAS
 SG_ Right_Angle_718 : 55|13@0- (0.0002,0) [-0.8192|0.819] "rad"  radar,ADAS
 SG_ Left_Angle_718 : 37|13@0- (0.0002,0) [-0.8192|0.819] "rad"  radar,ADAS
 SG_ Relative_Velocity_718 : 19|12@0- (0.05,0) [-102.4|102.35] "m/s"  radar,ADAS
 SG_ Longitudinal_Distance_718 : 15|12@0+ (0.05,0) [0|204.75] "m"  radar,ADAS

BO_ 1808 Video_Object_4_A: 8 Camera
 SG_ Class_710 : 58|3@0+ (1,0) [0|7] ""  radar,ADAS
 SG_ Identifier_710 : 7|7@0+ (1,0) [0|127] ""  radar,ADAS
 SG_ Right_Angle_710 : 55|13@0- (0.0002,0) [-0.8192|0.819] "rad"  radar,ADAS
 SG_ Left_Angle_710 : 37|13@0- (0.0002,0) [-0.8192|0.819] "rad"  radar,ADAS
 SG_ Relative_Velocity_710 : 19|12@0- (0.05,0) [-102.4|102.35] "m/s"  radar,ADAS
 SG_ Longitudinal_Distance_710 : 15|12@0+ (0.05,0) [0|204.75] "m"  radar,ADAS

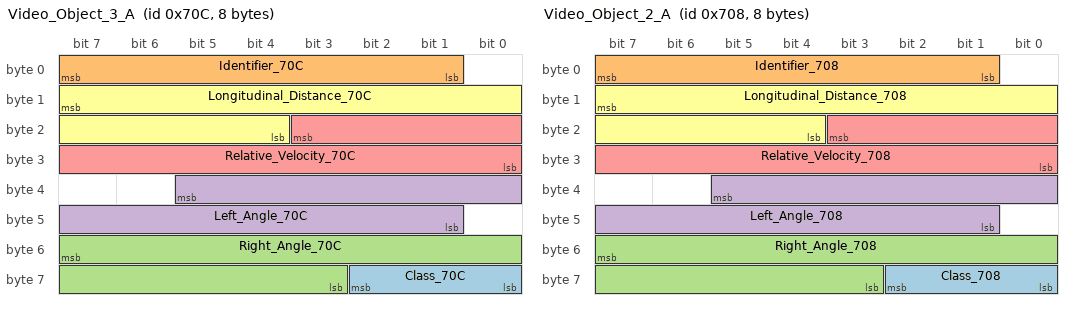
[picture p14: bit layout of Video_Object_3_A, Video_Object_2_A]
BO_ 1804 Video_Object_3_A: 8 Camera
 SG_ Class_70C : 58|3@0+ (1,0) [0|7] ""  radar,ADAS
 SG_ Identifier_70C : 7|7@0+ (1,0) [0|127] ""  radar,ADAS
 SG_ Right_Angle_70C : 55|13@0- (0.0002,0) [-0.8192|0.819] "rad"  radar,ADAS
 SG_ Left_Angle_70C : 37|13@0- (0.0002,0) [-0.8192|0.819] "rad"  radar,ADAS
 SG_ Relative_Velocity_70C : 19|12@0- (0.05,0) [-102.4|102.35] "m/s"  radar,ADAS
 SG_ Longitudinal_Distance_70C : 15|12@0+ (0.05,0) [0|204.75] "m"  radar,ADAS

BO_ 1800 Video_Object_2_A: 8 Camera
 SG_ Class_708 : 58|3@0+ (1,0) [0|7] ""  radar,ADAS
 SG_ Identifier_708 : 7|7@0+ (1,0) [0|127] ""  radar,ADAS
 SG_ Right_Angle_708 : 55|13@0- (0.0002,0) [-0.8192|0.819] "rad"  radar,ADAS
 SG_ Left_Angle_708 : 37|13@0- (0.0002,0) [-0.8192|0.819] "rad"  radar,ADAS
 SG_ Relative_Velocity_708 : 19|12@0- (0.05,0) [-102.4|102.35] "m/s"  radar,ADAS
 SG_ Longitudinal_Distance_708 : 15|12@0+ (0.05,0) [0|204.75] "m"  radar,ADAS

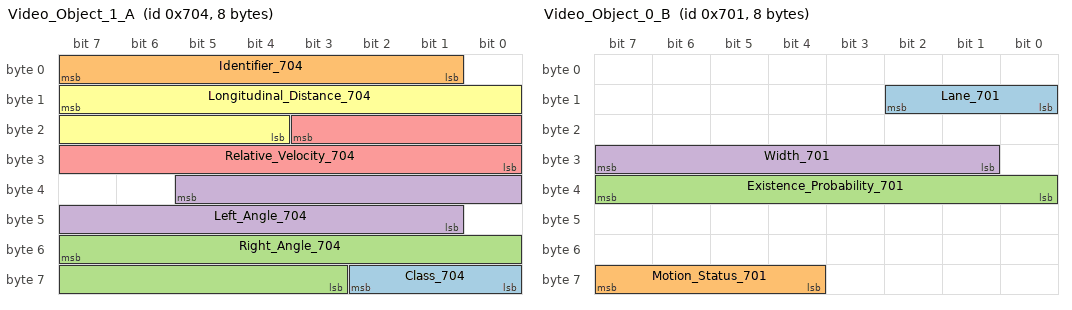
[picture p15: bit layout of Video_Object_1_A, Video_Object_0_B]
BO_ 1796 Video_Object_1_A: 8 Camera
 SG_ Class_704 : 58|3@0+ (1,0) [0|7] ""  radar,ADAS
 SG_ Identifier_704 : 7|7@0+ (1,0) [0|127] ""  radar,ADAS
 SG_ Right_Angle_704 : 55|13@0- (0.0002,0) [-0.8192|0.819] "rad"  radar,ADAS
 SG_ Left_Angle_704 : 37|13@0- (0.0002,0) [-0.8192|0.819] "rad"  radar,ADAS
 SG_ Relative_Velocity_704 : 19|12@0- (0.05,0) [-102.4|102.35] "m/s"  radar,ADAS
 SG_ Longitudinal_Distance_704 : 15|12@0+ (0.05,0) [0|204.75] "m"  radar,ADAS

BO_ 1793 Video_Object_0_B: 8 Camera
 SG_ Lane_701 : 10|3@0+ (1,0) [0|7] ""  ADAS,radar
 SG_ Motion_Status_701 : 63|4@0+ (1,0) [0|15] ""  radar,ADAS
 SG_ Existence_Probability_701 : 39|8@0+ (0.0039215686,0) [0|0.999999993] ""  radar,ADAS
 SG_ Width_701 : 31|7@0+ (0.05,0) [0|6.35] "m"  radar,ADAS

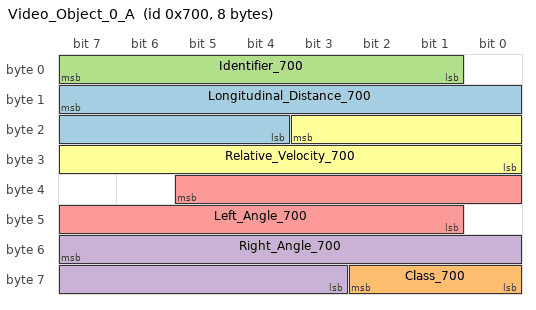
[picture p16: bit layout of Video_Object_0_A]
BO_ 1792 Video_Object_0_A: 8 Camera
 SG_ Longitudinal_Distance_700 : 15|12@0+ (0.05,0) [0|204.75] "m"  ADAS,radar
 SG_ Class_700 : 58|3@0+ (1,0) [0|7] ""  radar,ADAS
 SG_ Identifier_700 : 7|7@0+ (1,0) [0|127] ""  radar,ADAS
 SG_ Right_Angle_700 : 55|13@0- (0.0002,0) [-0.8192|0.819] "rad"  radar,ADAS
 SG_ Left_Angle_700 : 37|13@0- (0.0002,0) [-0.8192|0.819] "rad"  radar,ADAS
 SG_ Relative_Velocity_700 : 19|12@0- (0.05,0) [-102.4|102.35] "m/s"  radar,ADAS

BO_ 1526 Video_Data_General_B: 8 Camera
 SG_ SensorStatus : 30|4@0+ (1,0) [0|15] ""  radar,ADAS

CM_ SG_ 1812 Left_Angle_714 "in camera coords, this is directly proportional to the pixel values, so no small angle approximation
";
CM_ SG_ 1812 Right_Angle_714 "in camera coords, this is directly proportional to the pixel values, so no small angle approximation
";
CM_ SG_ 1836 Right_Angle_72C "in camera coords, this is directly proportional to the pixel values, so no small angle approximation
";
CM_ SG_ 1836 Left_Angle_72C "in camera coords, this is directly proportional to the pixel values, so no small angle approximation";
CM_ SG_ 1832 Right_Angle_728 "in camera coords, this is directly proportional to the pixel values, so no small angle approximation
";
CM_ SG_ 1832 Left_Angle_728 "in camera coords, this is directly proportional to the pixel values, so no small angle approximation";
CM_ SG_ 1523 Me_Line_Changed_5F3 "is one for one cycle when lane model switched.";
CM_ SG_ 1531 C1_5FB "57 degrees, 0.06 degrees resolution
";
CM_ SG_ 1531 C2_5FB "250m minimal radius
";
CM_ SG_ 1524 Me_Line_Changed_5F4 "is one for one cycle when lane model switched.";
CM_ SG_ 1534 C1_5FE "57 degrees, 0.06 degrees resolution
";
CM_ SG_ 1534 C2_5FE "250m minimal radius
";
CM_ SG_ 1532 Me_Line_Changed_5FC "is one for one cycle when lane model switched.";
CM_ SG_ 1530 C1_5FA "57 degrees, 0.06 degrees resolution
";
CM_ SG_ 1530 C2_5FA "250m minimal radius
";
CM_ SG_ 1535 Me_Line_Changed_5FF "is one for one cycle when lane model switched.";
CM_ SG_ 1533 C1_5FD "57 degrees, 0.06 degrees resolution
";
CM_ SG_ 1533 C2_5FD "250m minimal radius
";
CM_ SG_ 1828 Right_Angle_724 "in camera coords, this is directly proportional to the pixel values, so no small angle approximation
";
CM_ SG_ 1828 Left_Angle_724 "in camera coords, this is directly proportional to the pixel values, so no small angle approximation
";
CM_ SG_ 1824 Right_Angle_720 "in camera coords, this is directly proportional to the pixel values, so no small angle approximation
";
CM_ SG_ 1824 Left_Angle_720 "in camera coords, this is directly proportional to the pixel values, so no small angle approximation
";
CM_ SG_ 1820 Right_Angle_71C "in camera coords, this is directly proportional to the pixel values, so no small angle approximation
";
CM_ SG_ 1820 Left_Angle_71C "in camera coords, this is directly proportional to the pixel values, so no small angle approximation
";
CM_ SG_ 1816 Right_Angle_718 "in camera coords, this is directly proportional to the pixel values, so no small angle approximation
";
CM_ SG_ 1816 Left_Angle_718 "in camera coords, this is directly proportional to the pixel values, so no small angle approximation
";
CM_ SG_ 1808 Right_Angle_710 "in camera coords, this is directly proportional to the pixel values, so no small angle approximation
";
CM_ SG_ 1808 Left_Angle_710 "in camera coords, this is directly proportional to the pixel values, so no small angle approximation
";
CM_ SG_ 1804 Right_Angle_70C "in camera coords, this is directly proportional to the pixel values, so no small angle approximation
";
CM_ SG_ 1804 Left_Angle_70C "in camera coords, this is directly proportional to the pixel values, so no small angle approximation
";
CM_ SG_ 1800 Right_Angle_708 "in camera coords, this is directly proportional to the pixel values, so no small angle approximation
";
CM_ SG_ 1800 Left_Angle_708 "in camera coords, this is directly proportional to the pixel values, so no small angle approximation
";
CM_ SG_ 1796 Right_Angle_704 "in camera coords, this is directly proportional to the pixel values, so no small angle approximation
";
CM_ SG_ 1796 Left_Angle_704 "in camera coords, this is directly proportional to the pixel values, so no small angle approximation
";
CM_ SG_ 1792 Right_Angle_700 "in camera coords, this is directly proportional to the pixel values, so no small angle approximation
";
CM_ SG_ 1792 Left_Angle_700 "in camera coords, this is directly proportional to the pixel values, so no small angle approximation";
BA_DEF_ SG_  "GenSigEnvVarType" ENUM  "int","float","undef";
BA_DEF_ SG_  "GenSigSendType" ENUM  "Cyclic","OnWrite","OnWriteWithRepetition","OnChange","OnChangeWithRepetition","IfActive","IfActiveWithRepetition","NoSigSendType";
BA_DEF_ BO_  "GenMsgSendType" ENUM  "cyclic","spontaneous","cyclicIfActive","spontaneousWithDelay","cyclicAndSpontaneous","cyclicAndSpontaneousWithDelay","spontaneousWithRepetition","cyclicIfActiveAndSpontaneousWD";
BA_DEF_ BO_  "GenMsgNrOfRepetitions" INT 1 999999;
BA_DEF_ BO_  "GenMsgDelayTime" INT 1 1000;
BA_DEF_ BO_  "GenMsgCycleTime" INT 2 50000;
BA_DEF_ BO_  "NWM-Botschaft" ENUM  "nein","ja";
BA_DEF_ BO_  "GenMsgSendType " ENUM  "Cyclic","not_used","not_used","not_used","not_used","Cyclic","not_used","IfActive","NoMsgSendType";
BA_DEF_ BU_  "NWM-Knoten" ENUM  "nein","ja";
BA_DEF_  "GenEnvVarPrefix" STRING ;
BA_DEF_  "GenEnvVarEndingSnd" STRING ;
BA_DEF_  "GenEnvVarEndingDsp" STRING ;
BA_DEF_  "GenNWMTalkNM" STRING ;
BA_DEF_  "GenNWMGotoMode_BusSleep" STRING ;
BA_DEF_  "GenNWMGotoMode_Awake" STRING ;
BA_DEF_  "GenNWMApCanWakeUp" STRING ;
BA_DEF_  "GenNWMApCanSleep" STRING ;
BA_DEF_  "GenNWMApCanOn" STRING ;
BA_DEF_  "GenNWMApCanOff" STRING ;
BA_DEF_  "GenNWMApCanNormal" STRING ;
BA_DEF_  "GenNWMApBusSleep" STRING ;
BA_DEF_  "DBName" STRING ;
BA_DEF_  "BusType" STRING ;
BA_DEF_DEF_  "GenSigEnvVarType" "undef";
BA_DEF_DEF_  "GenSigSendType" "Cyclic";
BA_DEF_DEF_  "GenMsgSendType" "cyclic";
BA_DEF_DEF_  "GenMsgNrOfRepetitions" 1;
BA_DEF_DEF_  "GenMsgDelayTime" 1;
BA_DEF_DEF_  "GenMsgCycleTime" 33;
BA_DEF_DEF_  "NWM-Botschaft" "nein";
BA_DEF_DEF_  "GenMsgSendType " "NoMsgSendType";
BA_DEF_DEF_  "NWM-Knoten" "nein";
BA_DEF_DEF_  "GenEnvVarPrefix" "Env";
BA_DEF_DEF_  "GenEnvVarEndingSnd" "_";
BA_DEF_DEF_  "GenEnvVarEndingDsp" "Dsp_";
BA_DEF_DEF_  "GenNWMTalkNM" "TalkNM()";
BA_DEF_DEF_  "GenNWMGotoMode_BusSleep" "GotoMode_BusSleep()";
BA_DEF_DEF_  "GenNWMGotoMode_Awake" "GotoMode_Awake()";
BA_DEF_DEF_  "GenNWMApCanWakeUp" "apCanWakeUp()";
BA_DEF_DEF_  "GenNWMApCanSleep" "apCanSleep()";
BA_DEF_DEF_  "GenNWMApCanOn" "apCanOn()";
BA_DEF_DEF_  "GenNWMApCanOff" "apCanOff()";
BA_DEF_DEF_  "GenNWMApCanNormal" "apCanNormal()";
BA_DEF_DEF_  "GenNWMApBusSleep" "apBusSleep()";
BA_DEF_DEF_  "DBName" "";
BA_DEF_DEF_  "BusType" "";
BA_ "BusType" "CAN";
BA_ "DBName" "ADASECUSensorCAN_V1_20190226";
BA_ "GenMsgSendType " BO_ 1977 0;
BA_ "GenMsgCycleTime" BO_ 1977 40;
BA_ "GenMsgCycleTime" BO_ 1978 40;
VAL_ 1812 Identifier_714 0 "NoObject" ;
VAL_ 1812 Class_714 6 "General  object" 5 "pedestrian" 4 "bicycle" 3 "motorbike" 2 "car" 1 "truck" 0 "undecided" ;
VAL_ 1837 Motion_Status_72D 8 "Moving (oncoming)" 7 "Unknown (oncoming)" 6 "Stopped (oncoming)" 5 "Moving (movable)" 4 "Unknown (movable)" 3 "Stopped (movable)" 2 "Parked (never moved lights off)" 1 "Standing (never moved lights on)" 0 "not defined" ;
VAL_ 1837 Lane_72D 5 "next next lane right" 4 "next next lane left" 3 "next lane right" 2 "next lane left" 1 "ego lane" 0 "not assigned" ;
VAL_ 1977 Stat_StatusType 1 "Expanded_Status" 0 "Normal_Status" ;
VAL_ 1833 Motion_Status_729 8 "Moving (oncoming)" 7 "Unknown (oncoming)" 6 "Stopped (oncoming)" 5 "Moving (movable)" 4 "Unknown (movable)" 3 "Stopped (movable)" 2 "Parked (never moved lights off)" 1 "Standing (never moved lights on)" 0 "Not defined" ;
VAL_ 1833 Lane_729 5 "next next lane right" 4 "next next lane left" 3 "next lane right" 2 "next lane left" 1 "ego lane" 0 "not assigned" ;
VAL_ 1836 Class_72C 6 "General  object" 5 "pedestrian" 4 "bicycle" 3 "motorbike" 2 "car" 1 "truck" 0 "undecided" ;
VAL_ 1836 Identifier_72C 0 "NoObject" ;
VAL_ 1832 Class_728 6 "General  object" 5 "pedestrian" 4 "bicycle" 3 "motorbike" 2 "car" 1 "truck" 0 "undecided" ;
VAL_ 1832 Identifier_728 0 "NoObject" ;
VAL_ 1829 Motion_Status_725 8 "Moving (oncoming)" 7 "Unknown (oncoming)" 6 "Stopped (oncoming)" 5 "Moving (movable)" 4 "Unknown (movable)" 3 "Stopped (movable)" 2 "Parked (never moved lights off)" 1 "Standing (never moved lights on)" 0 "Not defined" ;
VAL_ 1829 Lane_725 5 "next next lane right" 4 "next next lane left" 3 "next lane right" 2 "next lane left" 1 "ego lane" 0 "not assigned" ;
VAL_ 1825 Motion_Status_721 8 "Moving (oncoming)" 7 "Unknown (oncoming)" 6 "Stopped (oncoming)" 5 "Moving (movable)" 4 "Unknown (movable)" 3 "Stopped (movable)" 2 "Parked (never moved lights off)" 1 "Standing (never moved lights on)" 0 "Not defined" ;
VAL_ 1825 Lane_721 5 "next next lane right" 4 "next next lane left" 3 "next lane right" 2 "next lane left" 1 "ego lane" 0 "not assigned" ;
VAL_ 1821 Motion_Status_71D 8 "Moving (oncoming)" 7 "Unknown (oncoming)" 6 "Stopped (oncoming)" 5 "Moving (movable)" 4 "Unknown (movable)" 3 "Stopped (movable)" 2 "Parked (never moved lights off)" 1 "Standing (never moved lights on)" 0 "Not defined" ;
VAL_ 1821 Lane_71D 5 "next next lane right" 4 "next next lane left" 3 "next lane right" 2 "next lane left" 1 "ego lane" 0 "not assigned" ;
VAL_ 1817 Motion_Status_719 8 "Moving (oncoming)" 7 "Unknown (oncoming)" 6 "Stopped (oncoming)" 5 "Moving (movable)" 4 "Unknown (movable)" 3 "Stopped (movable)" 2 "Parked (never moved lights off)" 1 "Standing (never moved lights on)" 0 "Not defined" ;
VAL_ 1817 Lane_719 5 "next next lane right" 4 "next next lane left" 3 "next lane right" 2 "next lane left" 1 "ego lane" 0 "not assigned" ;
VAL_ 1813 Motion_Status_715 8 "Moving (oncoming)" 7 "Unknown (oncoming)" 6 "Stopped (oncoming)" 5 "Moving (movable)" 4 "Unknown (movable)" 3 "Stopped (movable)" 2 "Parked (never moved lights off)" 1 "Standing (never moved lights on)" 0 "Not defined" ;
VAL_ 1813 Lane_715 5 "next next lane right" 4 "next next lane left" 3 "next lane right" 2 "next lane left" 1 "ego lane" 0 "not assigned" ;
VAL_ 1809 Motion_Status_711 8 "Moving (oncoming)" 7 "Unknown (oncoming)" 6 "Stopped (oncoming)" 5 "Moving (movable)" 4 "Unknown (movable)" 3 "Stopped (movable)" 2 "Parked (never moved lights off)" 1 "Standing (never moved lights on)" 0 "Not defined" ;
VAL_ 1809 Lane_711 5 "next next lane right" 4 "next next lane left" 3 "next lane right" 2 "next lane left" 1 "ego lane" 0 "not assigned" ;
VAL_ 1805 Motion_Status_70D 8 "Moving (oncoming)" 7 "Unknown (oncoming)" 6 "Stopped (oncoming)" 5 "Moving (movable)" 4 "Unknown (movable)" 3 "Stopped (movable)" 2 "Parked (never moved lights off)" 1 "Standing (never moved lights on)" 0 "Not defined" ;
VAL_ 1805 Lane_70D 5 "next next lane right" 4 "next next lane left" 3 "next lane right" 2 "next lane left" 1 "ego lane" 0 "not assigned" ;
VAL_ 1801 Motion_Status_709 8 "Moving (oncoming)" 7 "Unknown (oncoming)" 6 "Stopped (oncoming)" 5 "Moving (movable)" 4 "Unknown (movable)" 3 "Stopped (movable)" 2 "Parked (never moved lights off)" 1 "Standing (never moved lights on)" 0 "Not defined" ;
VAL_ 1801 Lane_709 5 "next next lane right" 4 "next next lane left" 3 "next lane right" 2 "next lane left" 1 "ego lane" 0 "not assigned" ;
VAL_ 1797 Motion_Status_705 8 "Moving (oncoming)" 7 "Unknown (oncoming)" 6 "Stopped (oncoming)" 5 "Moving (movable)" 4 "Unknown (movable)" 3 "Stopped (movable)" 2 "Parked (never moved lights off)" 1 "Standing (never moved lights on)" 0 "Not defined" ;
VAL_ 1797 Lane_705 5 "next next lane right" 4 "next next lane left" 3 "next lane right" 2 "next lane left" 1 "ego lane" 0 "not assigned" ;
VAL_ 1523 Me_Line_Changed_5F3 1 "crossing" 0 "not crossing" ;
VAL_ 1531 Line_Type_5FB 5 "bott's dotts" 4 "double lane mark" 3 "dashed" 2 "road edge" 1 "solid" 0 "undecided" ;
VAL_ 1531 Quality_5FB 3 "High" 2 "Medium_PredictedOrLowScore" 1 "Low2_InsufficientScore" 0 "Low1_NoLineDetected" ;
VAL_ 1524 Me_Line_Changed_5F4 3 "High" 2 "Medium_PredictedOrLowScore" 1 "Low2_InsufficientScore" 0 "Low1_NoLineDetected" ;
VAL_ 1534 Line_Type_5FE 5 "bott's dotts" 4 "double lane mark" 3 "dashed" 2 "road edge" 1 "solid" 0 "undecided" ;
VAL_ 1534 Quality_5FE 3 "High" 2 "Medium_PredictedOrLowScore" 1 "Low2_InsufficientScore" 0 "Low1_NoLineDetected" ;
VAL_ 1532 Me_Line_Changed_5FC 1 "crossing" 0 "not crossing" ;
VAL_ 1530 Line_Type_5FA 5 "bott's dotts" 4 "double lane mark" 3 "dashed" 2 "road edge" 1 "solid" 0 "undecided" ;
VAL_ 1530 Quality_5FA 3 "High" 2 "Medium_PredictedOrLowScore" 1 "Low2_InsufficientScore" 0 "Low1_NoLineDetected" ;
VAL_ 1535 Me_Line_Changed_5FF 1 "crossing" 0 "not crossing" ;
VAL_ 1533 Line_Type_5FD 5 "bott's dotts" 4 "double lane mark" 3 "dashed" 2 "road edge" 1 "solid" 0 "undecided" ;
VAL_ 1533 Quality_5FD 3 "High" 2 "Medium_PredictedOrLowScore" 1 "Low2_InsufficientScore" 0 "Low1_NoLineDetected" ;
VAL_ 1110 LaneModuleValid 1 "valid" 0 "not valid" ;
VAL_ 1110 Road_Type 2 "inner city" 1 "highway" 0 "unknown" ;
VAL_ 1110 Construction_Area 1 "construction area" 0 "not construction area" ;
VAL_ 1828 Class_724 6 "General  object" 5 "pedestrian" 4 "bicycle" 3 "motorbike" 2 "car" 1 "truck" 0 "undecided" ;
VAL_ 1828 Identifier_724 0 "NoObject" ;
VAL_ 1824 Class_720 6 "General  object" 5 "pedestrian" 4 "bicycle" 3 "motorbike" 2 "car" 1 "truck" 0 "undecided" ;
VAL_ 1824 Identifier_720 0 "NoObject" ;
VAL_ 1820 Class_71C 6 "General  object" 5 "pedestrian" 4 "bicycle" 3 "motorbike" 2 "car" 1 "truck" 0 "undecided" ;
VAL_ 1820 Identifier_71C 0 "NoObject" ;
VAL_ 1816 Class_718 6 "General  object" 5 "pedestrian" 4 "bicycle" 3 "motorbike" 2 "car" 1 "truck" 0 "undecided" ;
VAL_ 1816 Identifier_718 0 "NoObject" ;
VAL_ 1808 Class_710 6 "General  object" 5 "pedestrian" 4 "bicycle" 3 "motorbike" 2 "car" 1 "truck" 0 "undecided" ;
VAL_ 1808 Identifier_710 0 "NoObject" ;
VAL_ 1804 Class_70C 6 "General  object" 5 "pedestrian" 4 "bicycle" 3 "motorbike" 2 "car" 1 "truck" 0 "undecided" ;
VAL_ 1804 Identifier_70C 0 "NoObject" ;
VAL_ 1800 Class_708 6 "General  object" 5 "pedestrian" 4 "bicycle" 3 "motorbike" 2 "car" 1 "truck" 0 "undecided" ;
VAL_ 1800 Identifier_708 0 "NoObject" ;
VAL_ 1796 Class_704 6 "General  object" 5 "pedestrian" 4 "bicycle" 3 "motorbike" 2 "car" 1 "truck" 0 "undecided" ;
VAL_ 1796 Identifier_704 0 "NoObject" ;
VAL_ 1793 Lane_701 5 "next next lane right" 4 "next next lane left" 3 "next lane right" 2 "next lane left" 1 "ego lane" 0 "not assigned" ;
VAL_ 1793 Motion_Status_701 8 "Moving (oncoming)" 7 "Unknown (oncoming)" 6 "Stopped (oncoming)" 5 "Moving (movable)" 4 "Unknown (movable)" 3 "Stopped (movable)" 2 "Parked (never moved lights off)" 1 "Standing (never moved lights on)" 0 "Not defined" ;
VAL_ 1792 Class_700 6 "General  object" 5 "pedestrian" 4 "bicycle" 3 "motorbike" 2 "car" 1 "truck" 0 "undecided" ;
VAL_ 1792 Identifier_700 0 "NoObject" ;
VAL_ 1526 SensorStatus 15 "Reserved" 14 "Reserved" 13 "Reserved" 12 "Reserved" 11 "Reserved" 10 "Reserved" 9 "System fully operational" 7 "Camera Degraded" 6 "Reserved" 5 "Camera Blocked/No image" 3 "Blocked" 0 "system error" 8 "Reserved" 4 "Reserved" 2 "System Initializing/Warming Up" 1 "Status not available" ;
